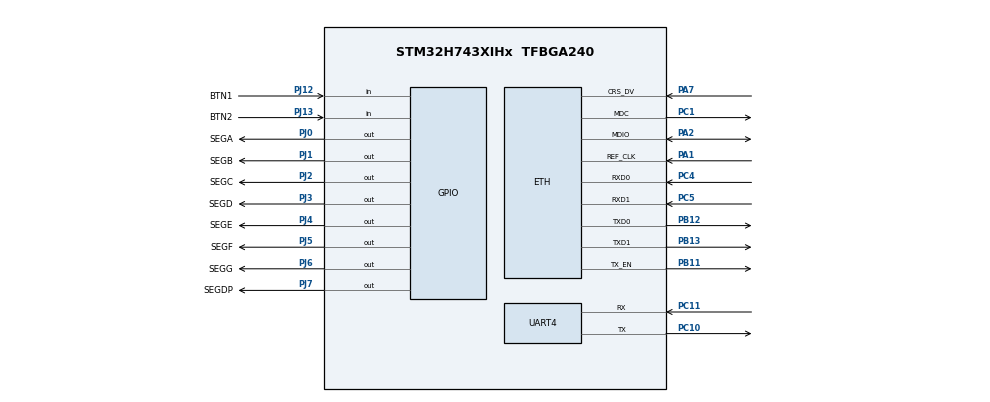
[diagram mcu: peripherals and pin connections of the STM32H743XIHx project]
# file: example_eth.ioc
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Mcu.Family=STM32H7
LWIP0.BSP.STBoard=false
RCC.CortexFreq_Value=400000000
RCC.HPRE=RCC_HCLK_DIV2
PH0-OSC_IN\ (PH0).Signal=RCC_OSC_IN
PC10.Signal=UART4_TX
PC15-OSC32_OUT\ (OSC32_OUT).Mode=LSE-External-Oscillator
CORTEX_M7.TypeExtField-Cortex_Memory_Protection_Unit_Region0_Settings=MPU_TEX_LEVEL1
PA2.GPIO_Speed=GPIO_SPEED_FREQ_HIGH
PJ6.GPIO_Label=SEGG
PA15\ (JTDI).Signal=DEBUG_JTDI
PC5.Mode=RMII
PB11.Signal=ETH_TX_EN
PB13.Signal=ETH_TXD1
PJ5.GPIO_Label=SEGF
RCC.SYSCLKSource=RCC_SYSCLKSOURCE_PLLCLK
ProjectManager.StackSize=0x400
PB11.GPIO_Speed=GPIO_SPEED_FREQ_HIGH
LWIP.NETMASK_ADDRESS=255.255.255.000
PJ6.Signal=GPIO_Output
PA14\ (JTCK/SWCLK).Signal=DEBUG_JTCK-SWCLK
PA15\ (JTDI).Mode=JTAG_5_pins
CORTEX_M7.Enable-Cortex_Memory_Protection_Unit_Region0_Settings=MPU_REGION_ENABLE
PJ13.GPIO_Label=BTN2
CORTEX_M7.IsBufferable-Cortex_Memory_Protection_Unit_Region1_Settings=MPU_ACCESS_BUFFERABLE
PJ2.Signal=GPIO_Output
NVIC.TIM17_IRQn=true\:0\:0\:false\:false\:true\:false\:false\:true
RCC.HCLKFreq_Value=200000000
NVIC.ETH_IRQn=true\:5\:0\:false\:false\:true\:true\:true\:true
PH1-OSC_OUT\ (PH1).Mode=HSE-External-Oscillator
RCC.HSE_VALUE=16000000
RCC.DIVM1=1
PC4.GPIO_Speed=GPIO_SPEED_FREQ_HIGH
LWIP.MEM_SIZE=16360
PJ7.GPIO_Label=SEGDP
PJ12.GPIO_Label=BTN1
PA14\ (JTCK/SWCLK).Mode=JTAG_5_pins
VP_FREERTOS_VS_CMSIS_V1.Mode=CMSIS_V1
LWIP0.BSP.solution=LAN8742
CORTEX_M7.DisableExec-Cortex_Memory_Protection_Unit_Region0_Settings=MPU_INSTRUCTION_ACCESS_DISABLE
CORTEX_M7.DisableExec-Cortex_Memory_Protection_Unit_Region1_Settings=MPU_INSTRUCTION_ACCESS_DISABLE
RCC.APB3Freq_Value=100000000
LWIP0.BSP.component=LAN8742
Mcu.Package=TFBGA240
PB12.Mode=RMII
NVIC.TimeBase=TIM17_IRQn
RCC.D1PPRE=RCC_APB3_DIV2
PJ12.Signal=GPIO_Input
CORTEX_M7.BaseAddress-Cortex_Memory_Protection_Unit_Region1_Settings=0x30040000
PJ4.Signal=GPIO_Output
NVIC.TimeBaseIP=TIM17
PJ1.Signal=GPIO_Output
PC11.Mode=Asynchronous
CORTEX_M7.Size-Cortex_Memory_Protection_Unit_Region1_Settings=MPU_REGION_SIZE_256B
PC14-OSC32_IN\ (OSC32_IN).Mode=LSE-External-Oscillator
PJ3.GPIO_Label=SEGD
RCC.APB4Freq_Value=100000000
CORTEX_M7.Enable-Cortex_Memory_Protection_Unit_Region1_Settings=MPU_REGION_ENABLE
PC5.Signal=ETH_RXD1
PB13.Mode=RMII
CORTEX_M7.IsShareable-Cortex_Memory_Protection_Unit_Region1_Settings=MPU_ACCESS_SHAREABLE
PH0-OSC_IN\ (PH0).Mode=HSE-External-Oscillator
PJ1.GPIO_Label=SEGB
PC4.Mode=RMII
LWIP.IP_ADDRESS=192.168.010.002
RCC.PLLSourceVirtual=RCC_PLLSOURCE_HSE
CORTEX_M7.CPU_ICache=Enabled
FREERTOS.Tasks01=defaultTask,0,256,StartDefaultTask,Default,NULL,Dynamic,NULL,NULL;myBlinkTask,-3,256,blinkLED,Default,NULL,Dynamic,NULL,NULL
PA7.Mode=RMII
LWIP0.BSP.i2caddr=0
PA13\ (JTMS/SWDIO).Mode=JTAG_5_pins
VP_SYS_VS_tim17.Mode=TIM17
PC11.Signal=UART4_RX
PC10.Mode=Asynchronous
PC4.Signal=ETH_RXD0
RCC.D2PPRE2=RCC_APB2_DIV2
RCC.D2PPRE1=RCC_APB1_DIV2
LWIP.LWIP_DHCP=0
PH1-OSC_OUT\ (PH1).Signal=RCC_OSC_OUT
VP_LWIP_VS_Enabled.Mode=Enabled
CORTEX_M7.MPU_Control=MPU_PRIVILEGED_DEFAULT
PJ7.Signal=GPIO_Output
PJ3.Signal=GPIO_Output
PB11.Mode=RMII
PB3\ (JTDO/TRACESWO).Signal=DEBUG_JTDO-SWO
ProjectManager.TargetToolchain=Makefile
PC15-OSC32_OUT\ (OSC32_OUT).Signal=RCC_OSC32_OUT
RCC.DIVN1=50
PB13.GPIO_Speed=GPIO_SPEED_FREQ_HIGH
CORTEX_M7.BaseAddress-Cortex_Memory_Protection_Unit_Region0_Settings=0x30040000
LWIP0.BSP.instance=LAN8742
RCC.USBFreq_Value=400000000
LWIP0.BSP.api=BSP_COMPONENT_DRIVER
PA1.Signal=ETH_REF_CLK
PB12.GPIO_Speed=GPIO_SPEED_FREQ_HIGH
board=custom
PJ4.GPIO_Label=SEGE
PA7.GPIO_Speed=GPIO_SPEED_FREQ_HIGH
RCC.APB2Freq_Value=100000000
PA1.Mode=RMII
PA1.GPIO_Speed=GPIO_SPEED_FREQ_MEDIUM
RCC.ADCFreq_Value=32250000
CORTEX_M7.AccessPermission-Cortex_Memory_Protection_Unit_Region0_Settings=MPU_REGION_FULL_ACCESS
PC1.GPIO_Speed=GPIO_SPEED_FREQ_HIGH
PB4\ (NJTRST).Mode=JTAG_5_pins
PJ0.Signal=GPIO_Output
Mcu.Name=STM32H743XIHx
CORTEX_M7.Size-Cortex_Memory_Protection_Unit_Region0_Settings=MPU_REGION_SIZE_32KB
PA2.Signal=ETH_MDIO
CORTEX_M7.AccessPermission-Cortex_Memory_Protection_Unit_Region1_Settings=MPU_REGION_FULL_ACCESS
RCC.SYSCLKFreq_VALUE=400000000
ETH.MediaInterface=HAL_ETH_RMII_MODE
LWIP.BSP.number=1
PC14-OSC32_IN\ (OSC32_IN).Signal=RCC_OSC32_IN
PJ5.Signal=GPIO_Output
PJ0.GPIO_Label=SEGA
ProjectManager.HeapSize=0x200
LWIP.Version=v2.1.2_Cube
NVIC.PriorityGroup=NVIC_PRIORITYGROUP_4
PC5.GPIO_Speed=GPIO_SPEED_FREQ_HIGH
PB3\ (JTDO/TRACESWO).Mode=JTAG_5_pins
PA2.Mode=RMII
RCC.D3PPRE=RCC_APB4_DIV2
CORTEX_M7.CPU_DCache=Enabled
LWIP0.BSP.name=Driver_PHY
RCC.APB1Freq_Value=100000000
PJ2.GPIO_Label=SEGC
PC1.Signal=ETH_MDC
PB12.Signal=ETH_TXD0
PA13\ (JTMS/SWDIO).Signal=DEBUG_JTMS-SWDIO
PC1.Mode=RMII
PJ13.Signal=GPIO_Input
PA7.Signal=ETH_CRS_DV
PB4\ (NJTRST).Signal=DEBUG_JTRST

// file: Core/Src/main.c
/* USER CODE BEGIN Header */
/**
  ******************************************************************************
  * @file           : main.c
  * @brief          : Main program body
  ******************************************************************************
  * @attention
  *
  * <h2><center>&copy; Copyright (c) 2021 STMicroelectronics.
  * All rights reserved.</center></h2>
  *
  * This software component is licensed by ST under Ultimate Liberty license
  * SLA0044, the "License"; You may not use this file except in compliance with
  * the License. You may obtain a copy of the License at:
  *                             www.st.com/SLA0044
  *
  ******************************************************************************
  */
/* USER CODE END Header */
#include "main.h"
#include "cmsis_os.h"
#include "lwip.h"
#include "usart.h"
#include "gpio.h"

void SystemClock_Config(void);
static void MPU_Config(void);
void MX_FREERTOS_Init(void);

int main(void)
{

  /* MPU Configuration--------------------------------------------------------*/
  MPU_Config();

  /* Enable I-Cache---------------------------------------------------------*/
  SCB_EnableICache();

  /* Enable D-Cache---------------------------------------------------------*/
  SCB_EnableDCache();

  /* MCU Configuration--------------------------------------------------------*/

  /* Reset of all peripherals, Initializes the Flash interface and the Systick. */
  HAL_Init();

  /* Configure the system clock */
  SystemClock_Config();

  /* Initialize all configured peripherals */
  MX_GPIO_Init();
  MX_UART4_Init();

  /* Call init function for freertos objects (in freertos.c) */
  MX_FREERTOS_Init();
  /* Start scheduler */
  osKernelStart();

  /* We should never get here as control is now taken by the scheduler */
  /* Infinite loop */
  while (1)
  {

  }
}

void SystemClock_Config(void)
{
  RCC_OscInitTypeDef RCC_OscInitStruct = {0};
  RCC_ClkInitTypeDef RCC_ClkInitStruct = {0};
  RCC_PeriphCLKInitTypeDef PeriphClkInitStruct = {0};

  /** Supply configuration update enable
  */
  HAL_PWREx_ConfigSupply(PWR_LDO_SUPPLY);
  /** Configure the main internal regulator output voltage
  */
  __HAL_PWR_VOLTAGESCALING_CONFIG(PWR_REGULATOR_VOLTAGE_SCALE1);

  while(!__HAL_PWR_GET_FLAG(PWR_FLAG_VOSRDY)) {}
  /** Initializes the RCC Oscillators according to the specified parameters
  * in the RCC_OscInitTypeDef structure.
  */
  RCC_OscInitStruct.OscillatorType = RCC_OSCILLATORTYPE_HSE;
  RCC_OscInitStruct.HSEState = RCC_HSE_ON;
  RCC_OscInitStruct.PLL.PLLState = RCC_PLL_ON;
  RCC_OscInitStruct.PLL.PLLSource = RCC_PLLSOURCE_HSE;
  RCC_OscInitStruct.PLL.PLLM = 1;
  RCC_OscInitStruct.PLL.PLLN = 50;
  RCC_OscInitStruct.PLL.PLLP = 2;
  RCC_OscInitStruct.PLL.PLLQ = 2;
  RCC_OscInitStruct.PLL.PLLR = 2;
  RCC_OscInitStruct.PLL.PLLRGE = RCC_PLL1VCIRANGE_3;
  RCC_OscInitStruct.PLL.PLLVCOSEL = RCC_PLL1VCOWIDE;
  RCC_OscInitStruct.PLL.PLLFRACN = 0;
  if (HAL_RCC_OscConfig(&RCC_OscInitStruct) != HAL_OK)
  {
    Error_Handler();
  }
  /** Initializes the CPU, AHB and APB buses clocks
  */
  RCC_ClkInitStruct.ClockType = RCC_CLOCKTYPE_HCLK|RCC_CLOCKTYPE_SYSCLK
                              |RCC_CLOCKTYPE_PCLK1|RCC_CLOCKTYPE_PCLK2
                              |RCC_CLOCKTYPE_D3PCLK1|RCC_CLOCKTYPE_D1PCLK1;
  RCC_ClkInitStruct.SYSCLKSource = RCC_SYSCLKSOURCE_PLLCLK;
  RCC_ClkInitStruct.SYSCLKDivider = RCC_SYSCLK_DIV1;
  RCC_ClkInitStruct.AHBCLKDivider = RCC_HCLK_DIV2;
  RCC_ClkInitStruct.APB3CLKDivider = RCC_APB3_DIV2;
  RCC_ClkInitStruct.APB1CLKDivider = RCC_APB1_DIV2;
  RCC_ClkInitStruct.APB2CLKDivider = RCC_APB2_DIV2;
  RCC_ClkInitStruct.APB4CLKDivider = RCC_APB4_DIV2;

  if (HAL_RCC_ClockConfig(&RCC_ClkInitStruct, FLASH_LATENCY_2) != HAL_OK)
  {
    Error_Handler();
  }
  PeriphClkInitStruct.PeriphClockSelection = RCC_PERIPHCLK_UART4;
  PeriphClkInitStruct.Usart234578ClockSelection = RCC_USART234578CLKSOURCE_D2PCLK1;
  if (HAL_RCCEx_PeriphCLKConfig(&PeriphClkInitStruct) != HAL_OK)
  {
    Error_Handler();
  }
}

/* MPU Configuration */

void MPU_Config(void)
{
  MPU_Region_InitTypeDef MPU_InitStruct = {0};

  /* Disables the MPU */
  HAL_MPU_Disable();
  /** Initializes and configures the Region and the memory to be protected
  */
  MPU_InitStruct.Enable = MPU_REGION_ENABLE;
  MPU_InitStruct.Number = MPU_REGION_NUMBER0;
  MPU_InitStruct.BaseAddress = 0x30040000;
  MPU_InitStruct.Size = MPU_REGION_SIZE_32KB;
  MPU_InitStruct.SubRegionDisable = 0x0;
  MPU_InitStruct.TypeExtField = MPU_TEX_LEVEL1;
  MPU_InitStruct.AccessPermission = MPU_REGION_FULL_ACCESS;
  MPU_InitStruct.DisableExec = MPU_INSTRUCTION_ACCESS_DISABLE;
  MPU_InitStruct.IsShareable = MPU_ACCESS_NOT_SHAREABLE;
  MPU_InitStruct.IsCacheable = MPU_ACCESS_NOT_CACHEABLE;
  MPU_InitStruct.IsBufferable = MPU_ACCESS_NOT_BUFFERABLE;

  HAL_MPU_ConfigRegion(&MPU_InitStruct);
  /** Initializes and configures the Region and the memory to be protected
  */
  MPU_InitStruct.Enable = MPU_REGION_ENABLE;
  MPU_InitStruct.Number = MPU_REGION_NUMBER1;
  MPU_InitStruct.BaseAddress = 0x30040000;
  MPU_InitStruct.Size = MPU_REGION_SIZE_256B;
  MPU_InitStruct.SubRegionDisable = 0x0;
  MPU_InitStruct.TypeExtField = MPU_TEX_LEVEL0;
  MPU_InitStruct.AccessPermission = MPU_REGION_FULL_ACCESS;
  MPU_InitStruct.DisableExec = MPU_INSTRUCTION_ACCESS_DISABLE;
  MPU_InitStruct.IsShareable = MPU_ACCESS_SHAREABLE;
  MPU_InitStruct.IsCacheable = MPU_ACCESS_NOT_CACHEABLE;
  MPU_InitStruct.IsBufferable = MPU_ACCESS_BUFFERABLE;

  HAL_MPU_ConfigRegion(&MPU_InitStruct);
  /* Enables the MPU */
  HAL_MPU_Enable(MPU_PRIVILEGED_DEFAULT);

}
void HAL_TIM_PeriodElapsedCallback(TIM_HandleTypeDef *htim)
{
  if (htim->Instance == TIM17) {
    HAL_IncTick();
  }
}

void Error_Handler(void)
{
  __disable_irq();
  while (1)
  {
  }
}

/************************ (C) COPYRIGHT STMicroelectronics *****END OF FILE****/

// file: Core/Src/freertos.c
/* USER CODE BEGIN Header */
/**
  ******************************************************************************
  * File Name          : freertos.c
  * Description        : Code for freertos applications
  ******************************************************************************
  * @attention
  *
  * <h2><center>&copy; Copyright (c) 2021 STMicroelectronics.
  * All rights reserved.</center></h2>
  *
  * This software component is licensed by ST under Ultimate Liberty license
  * SLA0044, the "License"; You may not use this file except in compliance with
  * the License. You may obtain a copy of the License at:
  *                             www.st.com/SLA0044
  *
  ******************************************************************************
  */
/* USER CODE END Header */

#include "FreeRTOS.h"
#include "task.h"
#include "main.h"
#include "cmsis_os.h"

osThreadId defaultTaskHandle;
osThreadId myBlinkTaskHandle;

void StartDefaultTask(void const * argument);
void blinkLED(void const * argument);

extern void MX_LWIP_Init(void);
void MX_FREERTOS_Init(void); /* (MISRA C 2004 rule 8.1) */

/* GetIdleTaskMemory prototype (linked to static allocation support) */
void vApplicationGetIdleTaskMemory( StaticTask_t **ppxIdleTaskTCBBuffer, StackType_t **ppxIdleTaskStackBuffer, uint32_t *pulIdleTaskStackSize );

/* USER CODE BEGIN GET_IDLE_TASK_MEMORY */
static StaticTask_t xIdleTaskTCBBuffer;
static StackType_t xIdleStack[configMINIMAL_STACK_SIZE];

void vApplicationGetIdleTaskMemory( StaticTask_t **ppxIdleTaskTCBBuffer, StackType_t **ppxIdleTaskStackBuffer, uint32_t *pulIdleTaskStackSize )
{
  *ppxIdleTaskTCBBuffer = &xIdleTaskTCBBuffer;
  *ppxIdleTaskStackBuffer = &xIdleStack[0];
  *pulIdleTaskStackSize = configMINIMAL_STACK_SIZE;
  /* place for user code */
}
/* USER CODE END GET_IDLE_TASK_MEMORY */

void MX_FREERTOS_Init(void) {

  /* Create the thread(s) */
  /* definition and creation of defaultTask */
  osThreadDef(defaultTask, StartDefaultTask, osPriorityNormal, 0, 256);
  defaultTaskHandle = osThreadCreate(osThread(defaultTask), NULL);

  /* definition and creation of myBlinkTask */
  osThreadDef(myBlinkTask, blinkLED, osPriorityIdle, 0, 256);
  myBlinkTaskHandle = osThreadCreate(osThread(myBlinkTask), NULL);

}

void StartDefaultTask(void const * argument)
{
  /* init code for LWIP */
  MX_LWIP_Init();
  for(;;)
  {
    osDelay(1);
  }
}

void blinkLED(void const * argument)
{
  /* USER CODE BEGIN blinkLED */
  /* Infinite loop */
  for(;;)
  {
    HAL_GPIO_TogglePin(SEGA_GPIO_Port, SEGA_Pin);
    osDelay(1000);
  }
  /* USER CODE END blinkLED */
}

/************************ (C) COPYRIGHT STMicroelectronics *****END OF FILE****/
